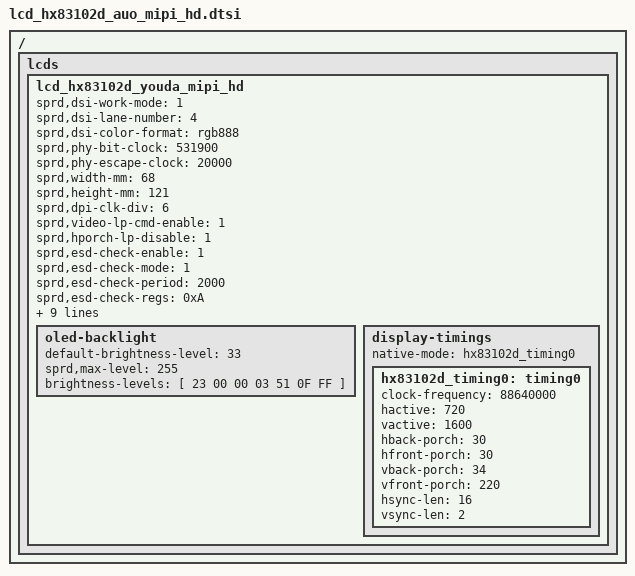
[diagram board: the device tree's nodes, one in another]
/ {
	fragment {
		target-path = "/";
		__overlay__ {
			lcds {

			lcd_hx83102d_youda_mipi_hd: lcd_hx83102d_youda_mipi_hd {
				sprd,dsi-work-mode = <1>; /* video burst mode*/
				sprd,dsi-lane-number = <4>;
				sprd,dsi-color-format = "rgb888";

				sprd,phy-bit-clock = <531900>;	/* kbps */
				sprd,phy-escape-clock = <20000>;/* kHz */
				sprd,width-mm = <68>;
				sprd,height-mm = <121>;
				sprd,dpi-clk-div = <6>;
				sprd,video-lp-cmd-enable = <1>;
				sprd,hporch-lp-disable = <1>;

				sprd,esd-check-enable = <1>;
				sprd,esd-check-mode = <1>;
				sprd,esd-check-period = <2000>;
				sprd,esd-check-regs = <0xA>;
				sprd,esd-return-code = <0x9D>;

				sprd,reset-on-sequence = <1 5>, <0 5>, <1 20>;
				sprd,reset-off-sequence = <1 5>;

				sprd,initial-command = [

					23 78 00 02 11 00

					39 00 00 04 B9 83 10 2D
					39 00 00 0C C0 30 30 00 00 19 42 00 08 00 1A 1B
					39 00 00 0C B1 22 00 2B 2B 31 42 4D 2F 08 08 08
					39 00 00 10 B2 00 00 06 40 00 20 BE 37 33 02 00 00 F4 90 D7
					39 00 00 0F B4 5A 55 5A 55 5A 55 5A 55 08 FF 08 20 00 FF
					23 00 00 02 CC 02
					39 00 00 31 D3 06 02 00 00 00 10 10 6F 00 66 58 17 17 00 00 32 10 17 00 17 32 16 64 06 64 32 10 00 00 00 00 00 00 00 00 00 00 00 00 00 03 2D 5A 55 03 2D 5A 55
					39 00 00 2D D5 18 18 18 18 25 24 25 24 2E 2D 2E 2D 18 18 18 18 09 08 18 18 01 00 0B 0A 03 02 0D 0C 05 04 0F 0E 07 06 21 20 21 20 18 18 18 18 18 18
					39 00 00 2D D6 18 18 18 18 20 21 20 21 18 18 18 18 2D 2E 2D 2E 06 07 18 18 0E 0F 04 05 0C 0D 02 03 0A 0B 00 01 08 09 24 25 24 25 18 18 18 18 18 18
					39 00 00 25 D8 AA AA AA AA AA A0 AA AA AA AA AA A0 AA AA 20 00 2A A0 AA AA 20 00 2A A0 00 00 00 00 00 00 00 00 00 00 00 00
					39 00 00 2F E0 0B 12 1C 24 2C 50 65 68 6B 66 7B 7C 7D 8A 84 89 92 A3 A1 51 58 62 65 0B 12 1C 24 2C 50 65 68 6B 66 7B 7C 7D 8A 84 89 92 A3 A1 51 58 62 76
					23 00 00 02 BD 01
					39 00 00 25 D8 AA AA AA AA AA A0 AA AA AA AA AA A0 00 00 00 00 00 00 00 00 00 00 00 00 00 00 00 00 00 00 00 00 00 00 00 00
					23 00 00 02 BD 02
					39 00 00 0D D8 FF FF FF FF FF F0 FF FF FF FF FF F0
					23 00 00 02 BD 03
					39 00 00 19 D8 AA AA AA AA AA A0 AA AA AA AA AA A0 FF FF EF FF FE A0 FF FF EF FF FE A0
					23 00 00 02 BD 00
					39 00 00 05 E7 FF 14 00 00
					23 00 00 02 BD 01
					23 00 00 02 E7 01
					23 00 00 02 BD 00
					39 00 00 03 D1 20 01
					39 00 00 14 BA 70 23 A8 83 B2 C0 C0 01 10 00 00 00 0D 3D 82 77 04 01 00
					23 00 00 02 BD 01
					23 00 00 02 CB 01
					23 00 00 02 BD 00
					39 00 00 06 CB 00 53 00 02 57
					39 00 00 08 BF FC 00 04 98 F6 00 4D
					23 00 00 02 BD 02
					39 00 00 09 B4 42 00 33 00 33 88 B3 00
					39 00 00 04 B1 7F 03 F5
					23 00 00 02 BD 00					
					23 00 00 02 35 00
					23 00 00 02 BD 02
					23 00 00 02 E4 02
					23 00 00 02 BD 00
					23 00 00 02 E9 CE
					23 00 00 02 BB 80
					23 00 00 02 E9 3F
					39 00 00 03 51 00 00
					39 00 00 05 C9 04 10 46 01
					23 05 00 02 55 03
					39 00 00 10 E4 2D 01 2C FF FF FF FF 1E 55 97 DE FF AA FF 03
					23 00 00 02 BD 01
					39 00 00 28 E4 23 23 23 23 23 23 23 23 23 23 23 23 23 23 23 23 23 23 23 23 23 23 23 23 1B 17 13 0F 0C 09 06 54 55 55 55 55 55 55 55
					23 00 00 02 BD 00
					23 00 00 02 53 2C

					23 14 00 02 29 00
				];

				sprd,sleep-in-command = [
					13 14 00 01 28
					13 78 00 01 10
				];

				sprd,sleep-out-command = [
					13 78 00 01 11
					13 14 00 01 29
				];

					oled-backlight {
						default-brightness-level = <33>;
						sprd,max-level = <255>;

						brightness-levels = [
							23 00 00 03 51 0F FF
							];
						};

					display-timings {
						native-mode = <&hx83102d_timing0>;

						hx83102d_timing0: timing0 {
									clock-frequency = <88640000>;
									hactive = <720>;
									vactive = <1600>;
									hback-porch = <30>;
									hfront-porch = <30>;
									vback-porch = <34>;
									vfront-porch = <220>;
									hsync-len = <16>;
									vsync-len = <2>;
						};
					};
				};
			};
		};
	};
};
